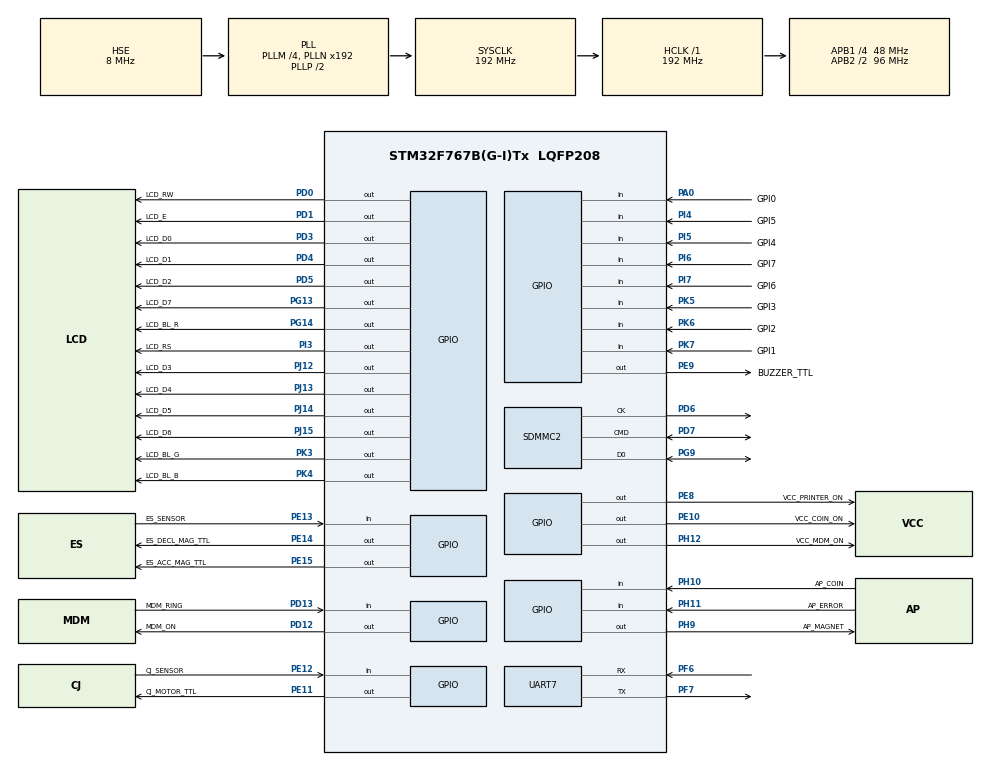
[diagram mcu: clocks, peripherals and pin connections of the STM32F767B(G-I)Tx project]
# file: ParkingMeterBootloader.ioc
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CORTEX_M7.default_mode_Activation=1
Dma.Request0=SDMMC2_RX
Dma.Request1=SDMMC2_TX
Dma.SDMMC2_RX.0.Direction=DMA_PERIPH_TO_MEMORY
Dma.SDMMC2_RX.0.FIFOMode=DMA_FIFOMODE_ENABLE
Dma.SDMMC2_RX.0.FIFOThreshold=DMA_FIFO_THRESHOLD_FULL
Dma.SDMMC2_RX.0.Instance=DMA2_Stream0
Dma.SDMMC2_RX.0.MemBurst=DMA_MBURST_INC4
Dma.SDMMC2_RX.0.MemDataAlignment=DMA_MDATAALIGN_WORD
Dma.SDMMC2_RX.0.MemInc=DMA_MINC_ENABLE
Dma.SDMMC2_RX.0.Mode=DMA_PFCTRL
Dma.SDMMC2_RX.0.PeriphBurst=DMA_PBURST_INC4
Dma.SDMMC2_RX.0.PeriphDataAlignment=DMA_PDATAALIGN_WORD
Dma.SDMMC2_RX.0.PeriphInc=DMA_PINC_DISABLE
Dma.SDMMC2_RX.0.Priority=DMA_PRIORITY_LOW
Dma.SDMMC2_TX.1.Direction=DMA_MEMORY_TO_PERIPH
Dma.SDMMC2_TX.1.FIFOMode=DMA_FIFOMODE_ENABLE
Dma.SDMMC2_TX.1.FIFOThreshold=DMA_FIFO_THRESHOLD_FULL
Dma.SDMMC2_TX.1.Instance=DMA2_Stream5
Dma.SDMMC2_TX.1.MemBurst=DMA_MBURST_INC4
Dma.SDMMC2_TX.1.MemDataAlignment=DMA_MDATAALIGN_WORD
Dma.SDMMC2_TX.1.MemInc=DMA_MINC_ENABLE
Dma.SDMMC2_TX.1.Mode=DMA_PFCTRL
Dma.SDMMC2_TX.1.PeriphBurst=DMA_PBURST_INC4
Dma.SDMMC2_TX.1.PeriphDataAlignment=DMA_PDATAALIGN_WORD
Dma.SDMMC2_TX.1.PeriphInc=DMA_PINC_DISABLE
Dma.SDMMC2_TX.1.Priority=DMA_PRIORITY_LOW
FATFS.USE_DMA_CODE_SD=1
FATFS._USE_LFN=2
Mcu.Family=STM32F7
Mcu.Name=STM32F767B(G-I)Tx
Mcu.Package=LQFP208
NVIC.DMA2_Stream0_IRQn=true\:0\:0\:false\:false\:true\:false\:true\:true
NVIC.DMA2_Stream5_IRQn=true\:0\:0\:false\:false\:true\:false\:true\:true
NVIC.PriorityGroup=NVIC_PRIORITYGROUP_4
NVIC.SDMMC2_IRQn=true\:0\:0\:false\:false\:true\:true\:true\:true
PA0/WKUP.GPIO_Label=GPI0
PA0/WKUP.Signal=GPIO_Input
PA1.Signal=UART4_RX
PB0.GPIO_Label=LIGHT_SENSOR
PB0.Signal=ADCx_IN8
PB1.GPIO_Label=VCC_SOLAR_MEASUREMENT
PB1.Signal=ADCx_IN9
PB10.Signal=USART3_TX
PB11.Signal=USART3_RX
PB12.Signal=UART5_RX
PB13.Signal=UART5_TX
PB14.Signal=USART1_TX
PB15.Signal=USART1_RX
PC1.GPIO_Label=VCC12_MEASUREMENT
PC1.Signal=ADCx_IN11
PC14/OSC32_IN.Mode=LSE-External-Oscillator
PC14/OSC32_IN.Signal=RCC_OSC32_IN
PC15/OSC32_OUT.Mode=LSE-External-Oscillator
PC15/OSC32_OUT.Signal=RCC_OSC32_OUT
PC2.GPIO_Label=VCC24_MEASUREMENT
PC2.Signal=ADCx_IN12
PC3.GPIO_Label=VCC5_MEASUREMENT
PC3.Signal=ADCx_IN13
PD0.GPIO_Label=LCD_RW
PD0.Signal=GPIO_Output
PD1.GPIO_Label=LCD_E
PD1.Signal=GPIO_Output
PD12.GPIO_Label=MDM_ON
PD12.Signal=GPIO_Output
PD13.GPIO_Label=MDM_RING
PD13.Signal=GPIO_Input
PD3.GPIO_Label=LCD_D0
PD3.Signal=GPIO_Output
PD4.GPIO_Label=LCD_D1
PD4.Signal=GPIO_Output
PD5.GPIO_Label=LCD_D2
PD5.Signal=GPIO_Output
PD6.Mode=SD_1_bit
PD6.Signal=SDMMC2_CK
PD7.Mode=SD_1_bit
PD7.Signal=SDMMC2_CMD
PE10.GPIO_Label=VCC_COIN_ON
PE10.Signal=GPIO_Output
PE11.GPIO_Label=CJ_MOTOR_TTL
PE11.Signal=GPIO_Output
PE12.GPIO_Label=CJ_SENSOR
PE12.Signal=GPIO_Input
PE13.GPIO_Label=ES_SENSOR
PE13.Signal=GPIO_Input
PE14.GPIO_Label=ES_DECL_MAG_TTL
PE14.Signal=GPIO_Output
PE15.GPIO_Label=ES_ACC_MAG_TTL
PE15.Signal=GPIO_Output
PE8.GPIO_Label=VCC_PRINTER_ON
PE8.Signal=GPIO_Output
PE9.GPIO_Label=BUZZER_TTL
PE9.Signal=GPIO_Output
PF6.Mode=Asynchronous
PF6.Signal=UART7_RX
PF7.Mode=Asynchronous
PF7.Signal=UART7_TX
PG10.Signal=SDMMC2_D1
PG11.Signal=SDMMC2_D2
PG12.Signal=SDMMC2_D3
PG13.GPIO_Label=LCD_D7
PG13.Signal=GPIO_Output
PG14.GPIO_Label=LCD_BL_R
PG14.Signal=GPIO_Output
PG9.Mode=SD_1_bit
PG9.Signal=SDMMC2_D0
PH0/OSC_IN.Mode=HSE-External-Oscillator
PH0/OSC_IN.Signal=RCC_OSC_IN
PH1/OSC_OUT.Mode=HSE-External-Oscillator
PH1/OSC_OUT.Signal=RCC_OSC_OUT
PH10.GPIO_Label=AP_COIN
PH10.Signal=GPIO_Input
PH11.GPIO_Label=AP_ERROR
PH11.Signal=GPIO_Input
PH12.GPIO_Label=VCC_MDM_ON
PH12.Signal=GPIO_Output
PH13.Signal=UART4_TX
PH9.GPIO_Label=AP_MAGNET
PH9.Signal=GPIO_Output
PI3.GPIO_Label=LCD_RS
PI3.Signal=GPIO_Output
PI4.GPIO_Label=GPI5
PI4.Signal=GPIO_Input
PI5.GPIO_Label=GPI4
PI5.Signal=GPIO_Input
PI6.GPIO_Label=GPI7
PI6.Signal=GPIO_Input
PI7.GPIO_Label=GPI6
PI7.Signal=GPIO_Input
PJ12.GPIO_Label=LCD_D3
PJ12.Signal=GPIO_Output
PJ13.GPIO_Label=LCD_D4
PJ13.Signal=GPIO_Output
PJ14.GPIO_Label=LCD_D5
PJ14.Signal=GPIO_Output
PJ15.GPIO_Label=LCD_D6
PJ15.Signal=GPIO_Output
PK3.GPIO_Label=LCD_BL_G
PK3.Signal=GPIO_Output
PK4.GPIO_Label=LCD_BL_B
PK4.Signal=GPIO_Output
PK5.GPIO_Label=GPI3
PK5.Signal=GPIO_Input
PK6.GPIO_Label=GPI2
PK6.Signal=GPIO_Input
PK7.GPIO_Label=GPI1
PK7.Signal=GPIO_Input
ProjectManager.HeapSize=0x200
ProjectManager.StackSize=0x400
ProjectManager.TargetToolchain=STM32CubeIDE
RCC.AHBFreq_Value=192000000
RCC.APB1CLKDivider=RCC_HCLK_DIV4
RCC.APB1Freq_Value=48000000
RCC.APB1TimFreq_Value=96000000
RCC.APB2CLKDivider=RCC_HCLK_DIV2
RCC.APB2Freq_Value=96000000
RCC.APB2TimFreq_Value=192000000
RCC.CortexFreq_Value=192000000
RCC.HCLKFreq_Value=192000000
RCC.HSE_VALUE=8000000
RCC.HSI_VALUE=16000000
RCC.PLL48CLockSelection=RCC_CLK48SOURCE_PLLSAIP
RCC.PLLM=4
RCC.PLLSAIP=RCC_PLLSAIP_DIV8
RCC.PLLSourceVirtual=RCC_PLLSOURCE_HSE
RCC.RTCClockSelection=RCC_RTCCLKSOURCE_LSE
RCC.SDMMC2ClockSelection=RCC_SDMMC2CLKSOURCE_CLK48
RCC.SYSCLKFreq_VALUE=192000000
RCC.SYSCLKSource=RCC_SYSCLKSOURCE_PLLCLK
RCC.USBFreq_Value=48000000
RCC.VCOOutputFreq_Value=384000000
SDMMC2.ClockDiv=2
SH.ADCx_IN11.0=ADC1_IN11
SH.ADCx_IN12.0=ADC1_IN12
SH.ADCx_IN13.0=ADC1_IN13
SH.ADCx_IN8.0=ADC1_IN8
SH.ADCx_IN9.0=ADC1_IN9
VP_FATFS_VS_SDIO.Mode=SDIO
VP_RNG_VS_RNG.Mode=RNG_Activate
board=custom

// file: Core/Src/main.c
/* USER CODE BEGIN Header */
/**
  ******************************************************************************
  * @file           : main.c
  * @brief          : Main program body
  ******************************************************************************
  * @attention
  *
  * Copyright (c) 2024 STMicroelectronics.
  * All rights reserved.
  *
  * This software is licensed under terms that can be found in the LICENSE file
  * in the root directory of this software component.
  * If no LICENSE file comes with this software, it is provided AS-IS.
  *
  ******************************************************************************
  */
/* USER CODE END Header */
#include "main.h"
#include "fatfs.h"

/* USER CODE BEGIN Includes */

#include "bootloader.h"
#include "lcd.h"

/* USER CODE END Includes */

RNG_HandleTypeDef hrng;

SD_HandleTypeDef hsd2;
DMA_HandleTypeDef hdma_sdmmc2_rx;
DMA_HandleTypeDef hdma_sdmmc2_tx;

UART_HandleTypeDef huart7;

void SystemClock_Config(void);
void PeriphCommonClock_Config(void);
static void MPU_Config(void);
static void MX_GPIO_Init(void);
static void MX_DMA_Init(void);
static void MX_RNG_Init(void);
static void MX_UART7_Init(void);
static void MX_SDMMC2_SD_Init(void);

/* USER CODE BEGIN 0 */
//override putchar -> printf redirected to uart
int __io_putchar( int ch )
{
   HAL_UART_Transmit( &huart7, (uint8_t *)&ch, 1, 0xFFFF );

   return ch;
}
/* USER CODE END 0 */

int main(void)
{

  /* MPU Configuration--------------------------------------------------------*/
  MPU_Config();

  /* MCU Configuration--------------------------------------------------------*/

  /* Reset of all peripherals, Initializes the Flash interface and the Systick. */
  HAL_Init();

  /* Configure the system clock */
  SystemClock_Config();

  /* Configure the peripherals common clocks */
  PeriphCommonClock_Config();

  /* Initialize all configured peripherals */
  MX_GPIO_Init();
  MX_DMA_Init();
  MX_RNG_Init();
  MX_UART7_Init();
  MX_SDMMC2_SD_Init();
  MX_FATFS_Init();
  /* USER CODE BEGIN 2 */
  __enable_irq();

  lcdInit();

  bootloaderMain();

  /* USER CODE END 2 */

  /* Infinite loop */
  while (1)
  {

  }
}

void SystemClock_Config(void)
{
  RCC_OscInitTypeDef RCC_OscInitStruct = {0};
  RCC_ClkInitTypeDef RCC_ClkInitStruct = {0};

  /** Configure LSE Drive Capability
  */
  HAL_PWR_EnableBkUpAccess();

  /** Configure the main internal regulator output voltage
  */
  __HAL_RCC_PWR_CLK_ENABLE();
  __HAL_PWR_VOLTAGESCALING_CONFIG(PWR_REGULATOR_VOLTAGE_SCALE1);

  /** Initializes the RCC Oscillators according to the specified parameters
  * in the RCC_OscInitTypeDef structure.
  */
  RCC_OscInitStruct.OscillatorType = RCC_OSCILLATORTYPE_HSE;
  RCC_OscInitStruct.HSEState = RCC_HSE_ON;
  RCC_OscInitStruct.PLL.PLLState = RCC_PLL_ON;
  RCC_OscInitStruct.PLL.PLLSource = RCC_PLLSOURCE_HSE;
  RCC_OscInitStruct.PLL.PLLM = 4;
  RCC_OscInitStruct.PLL.PLLN = 192;
  RCC_OscInitStruct.PLL.PLLP = RCC_PLLP_DIV2;
  RCC_OscInitStruct.PLL.PLLQ = 2;
  RCC_OscInitStruct.PLL.PLLR = 2;
  if (HAL_RCC_OscConfig(&RCC_OscInitStruct) != HAL_OK)
  {
    Error_Handler();
  }

  /** Activate the Over-Drive mode
  */
  if (HAL_PWREx_EnableOverDrive() != HAL_OK)
  {
    Error_Handler();
  }

  /** Initializes the CPU, AHB and APB buses clocks
  */
  RCC_ClkInitStruct.ClockType = RCC_CLOCKTYPE_HCLK|RCC_CLOCKTYPE_SYSCLK
                              |RCC_CLOCKTYPE_PCLK1|RCC_CLOCKTYPE_PCLK2;
  RCC_ClkInitStruct.SYSCLKSource = RCC_SYSCLKSOURCE_PLLCLK;
  RCC_ClkInitStruct.AHBCLKDivider = RCC_SYSCLK_DIV1;
  RCC_ClkInitStruct.APB1CLKDivider = RCC_HCLK_DIV4;
  RCC_ClkInitStruct.APB2CLKDivider = RCC_HCLK_DIV2;

  if (HAL_RCC_ClockConfig(&RCC_ClkInitStruct, FLASH_LATENCY_6) != HAL_OK)
  {
    Error_Handler();
  }
}

void PeriphCommonClock_Config(void)
{
  RCC_PeriphCLKInitTypeDef PeriphClkInitStruct = {0};

  /** Initializes the peripherals clock
  */
  PeriphClkInitStruct.PeriphClockSelection = RCC_PERIPHCLK_SDMMC2|RCC_PERIPHCLK_CLK48;
  PeriphClkInitStruct.PLLSAI.PLLSAIN = 192;
  PeriphClkInitStruct.PLLSAI.PLLSAIR = 2;
  PeriphClkInitStruct.PLLSAI.PLLSAIQ = 2;
  PeriphClkInitStruct.PLLSAI.PLLSAIP = RCC_PLLSAIP_DIV8;
  PeriphClkInitStruct.PLLSAIDivQ = 1;
  PeriphClkInitStruct.PLLSAIDivR = RCC_PLLSAIDIVR_2;
  PeriphClkInitStruct.Clk48ClockSelection = RCC_CLK48SOURCE_PLLSAIP;
  PeriphClkInitStruct.Sdmmc2ClockSelection = RCC_SDMMC2CLKSOURCE_CLK48;
  if (HAL_RCCEx_PeriphCLKConfig(&PeriphClkInitStruct) != HAL_OK)
  {
    Error_Handler();
  }
}

static void MX_RNG_Init(void)
{

  hrng.Instance = RNG;
  if (HAL_RNG_Init(&hrng) != HAL_OK)
  {
    Error_Handler();
  }

}

static void MX_SDMMC2_SD_Init(void)
{

  hsd2.Instance = SDMMC2;
  hsd2.Init.ClockEdge = SDMMC_CLOCK_EDGE_RISING;
  hsd2.Init.ClockBypass = SDMMC_CLOCK_BYPASS_DISABLE;
  hsd2.Init.ClockPowerSave = SDMMC_CLOCK_POWER_SAVE_DISABLE;
  hsd2.Init.BusWide = SDMMC_BUS_WIDE_1B;
  hsd2.Init.HardwareFlowControl = SDMMC_HARDWARE_FLOW_CONTROL_DISABLE;
  hsd2.Init.ClockDiv = 2;

}

static void MX_UART7_Init(void)
{

  huart7.Instance = UART7;
  huart7.Init.BaudRate = 115200;
  huart7.Init.WordLength = UART_WORDLENGTH_8B;
  huart7.Init.StopBits = UART_STOPBITS_1;
  huart7.Init.Parity = UART_PARITY_NONE;
  huart7.Init.Mode = UART_MODE_TX_RX;
  huart7.Init.HwFlowCtl = UART_HWCONTROL_NONE;
  huart7.Init.OverSampling = UART_OVERSAMPLING_16;
  huart7.Init.OneBitSampling = UART_ONE_BIT_SAMPLE_DISABLE;
  huart7.AdvancedInit.AdvFeatureInit = UART_ADVFEATURE_NO_INIT;
  if (HAL_UART_Init(&huart7) != HAL_OK)
  {
    Error_Handler();
  }

}

static void MX_DMA_Init(void)
{

  /* DMA controller clock enable */
  __HAL_RCC_DMA2_CLK_ENABLE();

  /* DMA interrupt init */
  /* DMA2_Stream0_IRQn interrupt configuration */
  HAL_NVIC_SetPriority(DMA2_Stream0_IRQn, 0, 0);
  HAL_NVIC_EnableIRQ(DMA2_Stream0_IRQn);
  /* DMA2_Stream5_IRQn interrupt configuration */
  HAL_NVIC_SetPriority(DMA2_Stream5_IRQn, 0, 0);
  HAL_NVIC_EnableIRQ(DMA2_Stream5_IRQn);

}

static void MX_GPIO_Init(void)
{
  GPIO_InitTypeDef GPIO_InitStruct = {0};

  /* GPIO Ports Clock Enable */
  __HAL_RCC_GPIOC_CLK_ENABLE();
  __HAL_RCC_GPIOF_CLK_ENABLE();
  __HAL_RCC_GPIOH_CLK_ENABLE();
  __HAL_RCC_GPIOA_CLK_ENABLE();
  __HAL_RCC_GPIOB_CLK_ENABLE();
  __HAL_RCC_GPIOE_CLK_ENABLE();
  __HAL_RCC_GPIOD_CLK_ENABLE();
  __HAL_RCC_GPIOI_CLK_ENABLE();
  __HAL_RCC_GPIOJ_CLK_ENABLE();
  __HAL_RCC_GPIOG_CLK_ENABLE();
  __HAL_RCC_GPIOK_CLK_ENABLE();

  /*Configure GPIO pin Output Level */
  HAL_GPIO_WritePin(GPIOE, VCC_PRINTER_ON_Pin|BUZZER_TTL_Pin|VCC_COIN_ON_Pin|CJ_MOTOR_TTL_Pin
                          |ES_DECL_MAG_TTL_Pin|ES_ACC_MAG_TTL_Pin, GPIO_PIN_RESET);

  /*Configure GPIO pin Output Level */
  HAL_GPIO_WritePin(GPIOH, AP_MAGNET_Pin|VCC_MDM_ON_Pin, GPIO_PIN_RESET);

  /*Configure GPIO pin Output Level */
  HAL_GPIO_WritePin(GPIOD, MDM_ON_Pin|LCD_RW_Pin|LCD_E_Pin|LCD_D0_Pin
                          |LCD_D1_Pin|LCD_D2_Pin, GPIO_PIN_RESET);

  /*Configure GPIO pin Output Level */
  HAL_GPIO_WritePin(LCD_RS_GPIO_Port, LCD_RS_Pin, GPIO_PIN_RESET);

  /*Configure GPIO pin Output Level */
  HAL_GPIO_WritePin(GPIOJ, LCD_D3_Pin|LCD_D4_Pin|LCD_D5_Pin|LCD_D6_Pin, GPIO_PIN_RESET);

  /*Configure GPIO pin Output Level */
  HAL_GPIO_WritePin(GPIOG, LCD_D7_Pin|LCD_BL_R_Pin, GPIO_PIN_RESET);

  /*Configure GPIO pin Output Level */
  HAL_GPIO_WritePin(GPIOK, LCD_BL_G_Pin|LCD_BL_B_Pin, GPIO_PIN_RESET);

  /*Configure GPIO pins : VCC12_MEASUREMENT_Pin VCC24_MEASUREMENT_Pin VCC5_MEASUREMENT_Pin */
  GPIO_InitStruct.Pin = VCC12_MEASUREMENT_Pin|VCC24_MEASUREMENT_Pin|VCC5_MEASUREMENT_Pin;
  GPIO_InitStruct.Mode = GPIO_MODE_ANALOG;
  GPIO_InitStruct.Pull = GPIO_NOPULL;
  HAL_GPIO_Init(GPIOC, &GPIO_InitStruct);

  /*Configure GPIO pin : GPI0_Pin */
  GPIO_InitStruct.Pin = GPI0_Pin;
  GPIO_InitStruct.Mode = GPIO_MODE_INPUT;
  GPIO_InitStruct.Pull = GPIO_NOPULL;
  HAL_GPIO_Init(GPI0_GPIO_Port, &GPIO_InitStruct);

  /*Configure GPIO pin : PA1 */
  GPIO_InitStruct.Pin = GPIO_PIN_1;
  GPIO_InitStruct.Mode = GPIO_MODE_AF_PP;
  GPIO_InitStruct.Pull = GPIO_NOPULL;
  GPIO_InitStruct.Speed = GPIO_SPEED_FREQ_VERY_HIGH;
  GPIO_InitStruct.Alternate = GPIO_AF8_UART4;
  HAL_GPIO_Init(GPIOA, &GPIO_InitStruct);

  /*Configure GPIO pins : LIGHT_SENSOR_Pin VCC_SOLAR_MEASUREMENT_Pin */
  GPIO_InitStruct.Pin = LIGHT_SENSOR_Pin|VCC_SOLAR_MEASUREMENT_Pin;
  GPIO_InitStruct.Mode = GPIO_MODE_ANALOG;
  GPIO_InitStruct.Pull = GPIO_NOPULL;
  HAL_GPIO_Init(GPIOB, &GPIO_InitStruct);

  /*Configure GPIO pins : VCC_PRINTER_ON_Pin BUZZER_TTL_Pin VCC_COIN_ON_Pin CJ_MOTOR_TTL_Pin
                           ES_DECL_MAG_TTL_Pin ES_ACC_MAG_TTL_Pin */
  GPIO_InitStruct.Pin = VCC_PRINTER_ON_Pin|BUZZER_TTL_Pin|VCC_COIN_ON_Pin|CJ_MOTOR_TTL_Pin
                          |ES_DECL_MAG_TTL_Pin|ES_ACC_MAG_TTL_Pin;
  GPIO_InitStruct.Mode = GPIO_MODE_OUTPUT_PP;
  GPIO_InitStruct.Pull = GPIO_NOPULL;
  GPIO_InitStruct.Speed = GPIO_SPEED_FREQ_LOW;
  HAL_GPIO_Init(GPIOE, &GPIO_InitStruct);

  /*Configure GPIO pins : CJ_SENSOR_Pin ES_SENSOR_Pin */
  GPIO_InitStruct.Pin = CJ_SENSOR_Pin|ES_SENSOR_Pin;
  GPIO_InitStruct.Mode = GPIO_MODE_INPUT;
  GPIO_InitStruct.Pull = GPIO_NOPULL;
  HAL_GPIO_Init(GPIOE, &GPIO_InitStruct);

  /*Configure GPIO pins : PB10 PB11 */
  GPIO_InitStruct.Pin = GPIO_PIN_10|GPIO_PIN_11;
  GPIO_InitStruct.Mode = GPIO_MODE_AF_PP;
  GPIO_InitStruct.Pull = GPIO_NOPULL;
  GPIO_InitStruct.Speed = GPIO_SPEED_FREQ_VERY_HIGH;
  GPIO_InitStruct.Alternate = GPIO_AF7_USART3;
  HAL_GPIO_Init(GPIOB, &GPIO_InitStruct);

  /*Configure GPIO pins : AP_MAGNET_Pin VCC_MDM_ON_Pin */
  GPIO_InitStruct.Pin = AP_MAGNET_Pin|VCC_MDM_ON_Pin;
  GPIO_InitStruct.Mode = GPIO_MODE_OUTPUT_PP;
  GPIO_InitStruct.Pull = GPIO_NOPULL;
  GPIO_InitStruct.Speed = GPIO_SPEED_FREQ_LOW;
  HAL_GPIO_Init(GPIOH, &GPIO_InitStruct);

  /*Configure GPIO pins : AP_COIN_Pin AP_ERROR_Pin */
  GPIO_InitStruct.Pin = AP_COIN_Pin|AP_ERROR_Pin;
  GPIO_InitStruct.Mode = GPIO_MODE_INPUT;
  GPIO_InitStruct.Pull = GPIO_NOPULL;
  HAL_GPIO_Init(GPIOH, &GPIO_InitStruct);

  /*Configure GPIO pins : PB12 PB13 */
  GPIO_InitStruct.Pin = GPIO_PIN_12|GPIO_PIN_13;
  GPIO_InitStruct.Mode = GPIO_MODE_AF_PP;
  GPIO_InitStruct.Pull = GPIO_NOPULL;
  GPIO_InitStruct.Speed = GPIO_SPEED_FREQ_VERY_HIGH;
  GPIO_InitStruct.Alternate = GPIO_AF8_UART5;
  HAL_GPIO_Init(GPIOB, &GPIO_InitStruct);

  /*Configure GPIO pins : PB14 PB15 */
  GPIO_InitStruct.Pin = GPIO_PIN_14|GPIO_PIN_15;
  GPIO_InitStruct.Mode = GPIO_MODE_AF_PP;
  GPIO_InitStruct.Pull = GPIO_NOPULL;
  GPIO_InitStruct.Speed = GPIO_SPEED_FREQ_VERY_HIGH;
  GPIO_InitStruct.Alternate = GPIO_AF4_USART1;
  HAL_GPIO_Init(GPIOB, &GPIO_InitStruct);

  /*Configure GPIO pins : MDM_ON_Pin LCD_RW_Pin LCD_E_Pin LCD_D0_Pin
                           LCD_D1_Pin LCD_D2_Pin */
  GPIO_InitStruct.Pin = MDM_ON_Pin|LCD_RW_Pin|LCD_E_Pin|LCD_D0_Pin
                          |LCD_D1_Pin|LCD_D2_Pin;
  GPIO_InitStruct.Mode = GPIO_MODE_OUTPUT_PP;
  GPIO_InitStruct.Pull = GPIO_NOPULL;
  GPIO_InitStruct.Speed = GPIO_SPEED_FREQ_LOW;
  HAL_GPIO_Init(GPIOD, &GPIO_InitStruct);

  /*Configure GPIO pin : MDM_RING_Pin */
  GPIO_InitStruct.Pin = MDM_RING_Pin;
  GPIO_InitStruct.Mode = GPIO_MODE_INPUT;
  GPIO_InitStruct.Pull = GPIO_NOPULL;
  HAL_GPIO_Init(MDM_RING_GPIO_Port, &GPIO_InitStruct);

  /*Configure GPIO pin : PH13 */
  GPIO_InitStruct.Pin = GPIO_PIN_13;
  GPIO_InitStruct.Mode = GPIO_MODE_AF_PP;
  GPIO_InitStruct.Pull = GPIO_NOPULL;
  GPIO_InitStruct.Speed = GPIO_SPEED_FREQ_VERY_HIGH;
  GPIO_InitStruct.Alternate = GPIO_AF8_UART4;
  HAL_GPIO_Init(GPIOH, &GPIO_InitStruct);

  /*Configure GPIO pin : LCD_RS_Pin */
  GPIO_InitStruct.Pin = LCD_RS_Pin;
  GPIO_InitStruct.Mode = GPIO_MODE_OUTPUT_PP;
  GPIO_InitStruct.Pull = GPIO_NOPULL;
  GPIO_InitStruct.Speed = GPIO_SPEED_FREQ_LOW;
  HAL_GPIO_Init(LCD_RS_GPIO_Port, &GPIO_InitStruct);

  /*Configure GPIO pins : LCD_D3_Pin LCD_D4_Pin LCD_D5_Pin LCD_D6_Pin */
  GPIO_InitStruct.Pin = LCD_D3_Pin|LCD_D4_Pin|LCD_D5_Pin|LCD_D6_Pin;
  GPIO_InitStruct.Mode = GPIO_MODE_OUTPUT_PP;
  GPIO_InitStruct.Pull = GPIO_NOPULL;
  GPIO_InitStruct.Speed = GPIO_SPEED_FREQ_LOW;
  HAL_GPIO_Init(GPIOJ, &GPIO_InitStruct);

  /*Configure GPIO pins : LCD_D7_Pin LCD_BL_R_Pin */
  GPIO_InitStruct.Pin = LCD_D7_Pin|LCD_BL_R_Pin;
  GPIO_InitStruct.Mode = GPIO_MODE_OUTPUT_PP;
  GPIO_InitStruct.Pull = GPIO_NOPULL;
  GPIO_InitStruct.Speed = GPIO_SPEED_FREQ_LOW;
  HAL_GPIO_Init(GPIOG, &GPIO_InitStruct);

  /*Configure GPIO pins : LCD_BL_G_Pin LCD_BL_B_Pin */
  GPIO_InitStruct.Pin = LCD_BL_G_Pin|LCD_BL_B_Pin;
  GPIO_InitStruct.Mode = GPIO_MODE_OUTPUT_PP;
  GPIO_InitStruct.Pull = GPIO_NOPULL;
  GPIO_InitStruct.Speed = GPIO_SPEED_FREQ_LOW;
  HAL_GPIO_Init(GPIOK, &GPIO_InitStruct);

  /*Configure GPIO pins : GPI3_Pin GPI2_Pin GPI1_Pin */
  GPIO_InitStruct.Pin = GPI3_Pin|GPI2_Pin|GPI1_Pin;
  GPIO_InitStruct.Mode = GPIO_MODE_INPUT;
  GPIO_InitStruct.Pull = GPIO_NOPULL;
  HAL_GPIO_Init(GPIOK, &GPIO_InitStruct);

  /*Configure GPIO pins : GPI5_Pin GPI4_Pin GPI7_Pin GPI6_Pin */
  GPIO_InitStruct.Pin = GPI5_Pin|GPI4_Pin|GPI7_Pin|GPI6_Pin;
  GPIO_InitStruct.Mode = GPIO_MODE_INPUT;
  GPIO_InitStruct.Pull = GPIO_NOPULL;
  HAL_GPIO_Init(GPIOI, &GPIO_InitStruct);

}

 /* MPU Configuration */

void MPU_Config(void)
{
  MPU_Region_InitTypeDef MPU_InitStruct = {0};

  /* Disables the MPU */
  HAL_MPU_Disable();

  /** Initializes and configures the Region and the memory to be protected
  */
  MPU_InitStruct.Enable = MPU_REGION_ENABLE;
  MPU_InitStruct.Number = MPU_REGION_NUMBER0;
  MPU_InitStruct.BaseAddress = 0x0;
  MPU_InitStruct.Size = MPU_REGION_SIZE_4GB;
  MPU_InitStruct.SubRegionDisable = 0x87;
  MPU_InitStruct.TypeExtField = MPU_TEX_LEVEL0;
  MPU_InitStruct.AccessPermission = MPU_REGION_NO_ACCESS;
  MPU_InitStruct.DisableExec = MPU_INSTRUCTION_ACCESS_DISABLE;
  MPU_InitStruct.IsShareable = MPU_ACCESS_SHAREABLE;
  MPU_InitStruct.IsCacheable = MPU_ACCESS_NOT_CACHEABLE;
  MPU_InitStruct.IsBufferable = MPU_ACCESS_NOT_BUFFERABLE;

  HAL_MPU_ConfigRegion(&MPU_InitStruct);
  /* Enables the MPU */
  HAL_MPU_Enable(MPU_PRIVILEGED_DEFAULT);

}

void Error_Handler(void)
{
  __disable_irq();
  while (1)
  {
  }
}
